# pmac_tx_secure register map
Vendor: Texas Instruments
Peripheral module from a debugger description file (folder CC35X1E).
Registers are 32-bit, access per field, reset 0x0 unless marked. A register's access mark holds for its fields unless they carry their own. Offsets are as the file gives them; lines under a group give offsets from that group; [hi:lo] are bit positions; {n}, {i} and the like mark numbered series; 'fields as' and 'values as' point back to an identical list; <NAME> marks a mode.

## pmac_tx_secure (part 1 of 3)
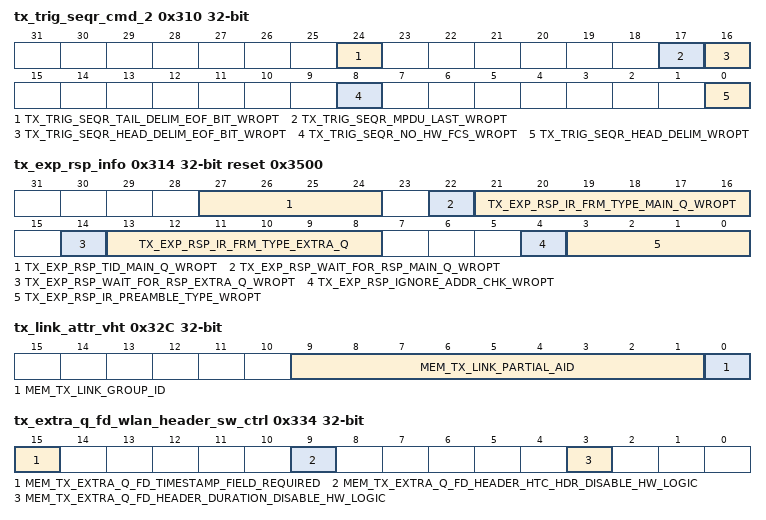
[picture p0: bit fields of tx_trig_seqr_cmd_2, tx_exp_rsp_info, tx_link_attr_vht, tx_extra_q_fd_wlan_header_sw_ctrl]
0x310 tx_trig_seqr_cmd_2
  [24] TX_TRIG_SEQR_TAIL_DELIM_EOF_BIT_WROPT rw — Set 1 - EOF field is present in tail delimiter. Set 0 - EOF field is not present in tail delimiter. EOF (end of frame indication) - When set to 1 in the tail delimiter (or what is called EOF MPDU delimiter) it indicates to the recipient MAC that all MPDUs have been received and that receive processing can cease. Note, tail delimiter present between MPDU in an A-MPDU (due to density requirement) shall set EOF bit to 0, unless it is the last MPDU, and symbol padding is required.
  [17] TX_TRIG_SEQR_MPDU_LAST_WROPT rw — Set 1 - Indicate last transmitted MPDU in current PPDU. Set 0 - Part of A-MPDU, followed by more MPDU in current PPDU,
  [16] TX_TRIG_SEQR_HEAD_DELIM_EOF_BIT_WROPT rw — Set 1 - EOF field is present in head delimiter. Set 0 - EOF field is not present in head delimiter. EOF (end of frame indication) - this field is present in MPDU head delimiter and have several usages: 1. VHT/HE : S-MPDU in VHT/HE PPDU is always carried in an A-MPDU structure , the EOF in the head delimiter is used to indicate that this A-MPDU is a Single MPDU (S-MPDU). Meaning EOF bit in head delimiter will be always set to 1, regardless of whether it requires an ACK or NOT. 2. HE : A-MPDU in VHT/HE PPDU, the EOF bit is used to determine whether certain MPDUs in the transmitted aggregation solicit an ACK response. 3. HT : A-MPDU in HT PPDU, EOF in Head delimiter is always set to 0.
  [8] TX_TRIG_SEQR_NO_HW_FCS_WROPT rw — Set 1 - FCS will be inserted at the end of frame. Set 0 - Otherwise.
  [0] TX_TRIG_SEQR_HEAD_DELIM_WROPT rw — Set 1 - TX Sequencer will insert Head Delimiter to current transmitted MPDU. Set 0 - TX Sequencer will not insert Head Delimiter to current transmitted MPDU. 0 - 11n/legacy MPDU. 1 - 11n/11ax/11ac A-MPDU or when sending S-MPDU (11ax/11ac).
0x314 tx_exp_rsp_info reset 0x3500
  [27:24] TX_EXP_RSP_TID_MAIN_Q_WROPT rw — This value is set by the TX Trigger module, and determine the TID of the QoS Data frames that were transmitted from main queue.
  [22] TX_EXP_RSP_WAIT_FOR_RSP_MAIN_Q_WROPT rw — This value is set by the TX Trigger module, and determine if there is a need to wait for a response for the transmitted frame from the main queue.
  [21:16] TX_EXP_RSP_IR_FRM_TYPE_MAIN_Q_WROPT rw — Expected response frame type, this value is set by the TX Trigger module, and used by the TX status machine/Exchange to determine the tx status of the transmitted frame. This value is set when transmitting a frame from the main queue in a complex aggregation constellation.
  [14] TX_EXP_RSP_WAIT_FOR_RSP_EXTRA_Q_WROPT rw — This value is set by the TX Trigger module, and determine if there is a need to wait for a response for the transmitted frame from the extra queue.
  [13:8] TX_EXP_RSP_IR_FRM_TYPE_EXTRA_Q ro — Expected response frame type, this value is set by the TX Trigger module, and used by the TX status machine/Exchange to determine the tx status of the transmitted frame. This value is set when transmitting a frame (mngt/ctrl frames) from the extra queue in a complex aggregation constellation.
  [4] TX_EXP_RSP_IGNORE_ADDR_CHK_WROPT rw — This value is set by the TX Trigger module and determines if there is a need to compare received address. This bit is needed as some responses can be transmitted by peer as a broadcast.
  [3:0] TX_EXP_RSP_IR_PREAMBLE_TYPE_WROPT rw — Expected response preamble, this value is set by the TX Trigger module, and used by the access module to load RX timeout counter with the appropriate value. Note, the time for the response to arrive (indication to PMAC) depends on the length and rate of the response preamble.
0x318 tx_exp_rsp_ra_h ro
  [15:0] TX_EXP_RSP_RA_H — Expected response receive address (47:32) set by TX Trigger module for the use of TX status machine. This value is compared in the TX status machine with the actual recieved address, to determine tx status.
0x31C tx_exp_rsp_ra_l ro
  [31:0] TX_EXP_RSP_RA_L — Expected response receive address (31:0) set by TX Trigger module for the use of TX status machine. This value is compared in the TX status machine with the actual recieved address, to determine tx status.
0x320 tx_trig_pre_fec_mac_pad
  [15:0] TX_TRIG_PRE_FEC_MAC_PAD_WROPT rw — Number of padding bytes done by the PMAC , the pad bytes are required when the transmitted tx frame length is missing bytes to complete certain constellation symbols. This value is retrieved from Duration Calculation module by the TX Trigger module. This value is passed to the TX Sequencer, which performs the padding (up to 3 octets or using tail-delimiters).
0x324 tx_role_mac_addr_msb
  [15:0] MEM_TX_ROLE_MAC_ADDR_MSB rw — MAC address (47:32) set by SW in Role DB, used by trigger module as TA field in WLAN header when generating QoS-Null frames.
0x328 tx_role_mac_addr_lsb rw
  [31:0] MEM_TX_ROLE_MAC_ADDR_LSB — MAC address (32:0) set by SW in Role DB, used by trigger module as TA field in WLAN header when generating QoS-Null frames.
0x32C tx_link_attr_vht
  [9:1] MEM_TX_LINK_PARTIAL_AID rw — Partial AID is included in SU to provide an earlier indication to the PHY so it can determine if it is the intended recipient of the packet. The MAC configures the PHY with the value that identifies the STA. Addressed to AP: BSSID[39:47] Addressed to Mesh STA: RA[39:47] Addressed to STA: (AID + (BSSID[44:47] xor BSSID[40:43]) << 5) mod 2^9
  [0] MEM_TX_LINK_GROUP_ID rw — Set Group-ID bit: 0 - vht_sig_a1[9:4] = 6'b000000 (dec 0 ) 1 - vht_sig_a1[9:4] = 6'b111111 (dec 63 )
0x330 tx_scrpt_hw_indication_sel
  [0] TX_SCRPT_HW_INDICATION_SEL_WROPT rw — Select HW indication group. Initial value on each script start is attribute bit 2 value. Set 0 - First Group. Set 1 - Second Group.
0x334 tx_extra_q_fd_wlan_header_sw_ctrl
  [15] MEM_TX_EXTRA_Q_FD_TIMESTAMP_FIELD_REQUIRED rw, [9] MEM_TX_EXTRA_Q_FD_HEADER_HTC_HDR_DISABLE_HW_LOGIC rw, [3] MEM_TX_EXTRA_Q_FD_HEADER_DURATION_DISABLE_HW_LOGIC rw
0x338 tx_ac4_queue_acc_length rw
  [31:0] TX_AC4_QUEUE_ACC_LENGTH_WROPT
0x33C tx_ac5_queue_acc_length rw
  [31:0] TX_AC5_QUEUE_ACC_LENGTH_WROPT
0x340 tx_ac_queue_inc_dec_length
  [17:0] TX_AC_QUEUE_INC_DEC_LENGTH_WROPT rw — Increment or decrement specific AC queue length. [13:0]: Number of bytes to increment/decrement [16:14]: Select AC [17]: Select operation. 0x0 Decrement. 0x1 Increment
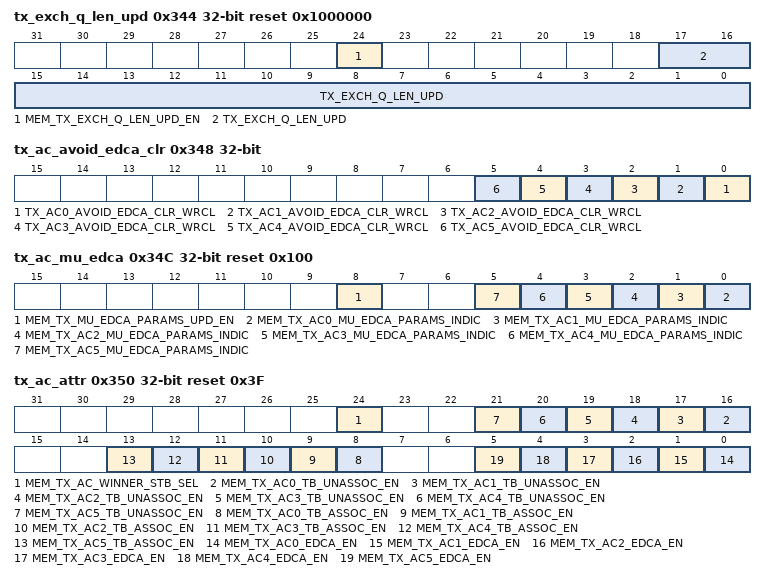
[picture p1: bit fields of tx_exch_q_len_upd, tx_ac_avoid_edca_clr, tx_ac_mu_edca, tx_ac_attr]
0x344 tx_exch_q_len_upd reset 0x1000000
  [24] MEM_TX_EXCH_Q_LEN_UPD_EN rw — Enable Tx exchange HW to decrement AC queue length when necessary
  [17:0] TX_EXCH_Q_LEN_UPD ro — TX exchange queue length update [13:0]: Number of bytes to increment/decrement [16:14]: Select AC [17]: Select operation. 0x0 Decrement. 0x1 Increment
0x348 tx_ac_avoid_edca_clr — writing '1' to one of the bits will create a pulse that will clear EDCA avoidance bit in AC_CTRL Machine.
  [n] TX_AC{n}_AVOID_EDCA_CLR_WRCL wo (n=0..5)
0x34C tx_ac_mu_edca reset 0x100
  [8] MEM_TX_MU_EDCA_PARAMS_UPD_EN rw — Set 0 : MU EDCA parameters replacement is not enabled. Set 1 : MU EDCA parameters replacement is enabled. HW will trigger IRQ to SW if one of the AC was seleted for the last TB transmition, and parameter update is required. AC CTRL FSM will avoid competing for 'AIR' untill SW clears the AVOID EDCA bit. Note, although AC is not competing for transmission, candidate/exchange are still operating on this AC in order to clear expired frames.
  [n] MEM_TX_AC{n}_MU_EDCA_PARAMS_INDIC rw (n=0..5) — Set 0 : Regular EDCA 'air competition' parameters are set by SW. Set 1 : Worst EDCA 'air competition' parameters are set by SW.
0x350 tx_ac_attr reset 0x3F
  [24] MEM_TX_AC_WINNER_STB_SEL rw — Set 0 : All AC Manager CTRL use tx_winner_stb. (Default - As Legacy LSB-PG1) Set 1 : All AC Manager CTRL use tx_winner_stb_synched. (New Option for LSB-PG2)
  [n+16] MEM_TX_AC{n}_TB_UNASSOC_EN rw (n=0..5) — Set 1 : AC is allowed to participate in TB un-associated transmission. Set 0 : O.W.
  [n+8] MEM_TX_AC{n}_TB_ASSOC_EN rw (n=0..5) — Set 1 : AC is allowed to participate in TB associated transmission. Set 0 : O.W.
  [n] MEM_TX_AC{n}_EDCA_EN rw (n=0..5) — Set 1 : AC is allowed to compete for EDCA transmission. Set 0 : O.W.
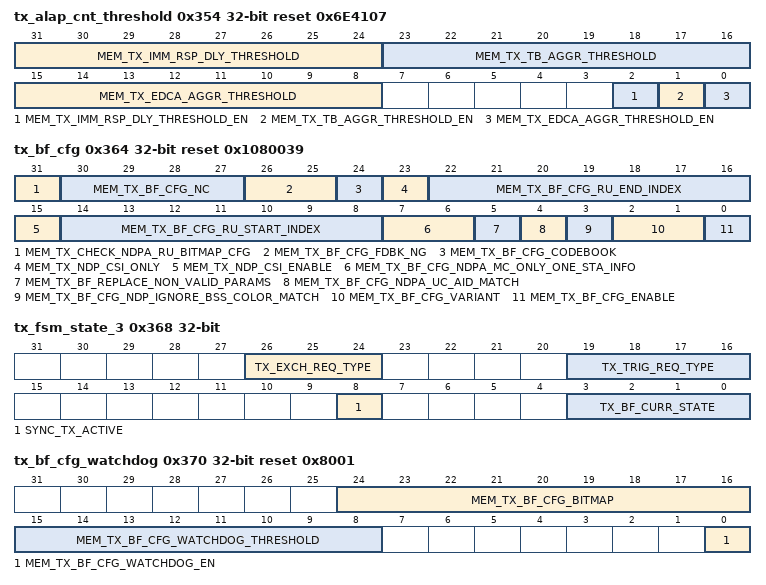
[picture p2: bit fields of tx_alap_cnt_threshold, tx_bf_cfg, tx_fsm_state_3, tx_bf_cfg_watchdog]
0x354 tx_alap_cnt_threshold reset 0x6E4107 — The ALAP Counter purpose is to sync HW to a certain point of time after tx winner. counter resolution is 1/5 us. count clear - on every tx winner. count increment - increment every useddiv_stb up to 256 (51 us). upon reaching a thresholds, done indication is generated. tx_alap_ctr_imm_rsp_dly_dn - scripter HW indication. tx_alap_ctr_tb_aggr_dn - aggregation machine in TX trigger will stop adding frames to TB aggregation. tx_alap_ctr_edca_aggr_dn - aggregation machine in TX trigger will stop adding frames to EDCA aggregation.
  [31:24] MEM_TX_IMM_RSP_DLY_THRESHOLD rw
  [23:16] MEM_TX_TB_AGGR_THRESHOLD rw — TB data ready is 29.8 us
  [15:8] MEM_TX_EDCA_AGGR_THRESHOLD rw — EDCA length ready is after 15.6us.
  [2] MEM_TX_IMM_RSP_DLY_THRESHOLD_EN rw
  [1] MEM_TX_TB_AGGR_THRESHOLD_EN rw
  [0] MEM_TX_EDCA_AGGR_THRESHOLD_EN rw
0x358 tx_hw_gen_frm_8 ro
0x35C tx_hw_gen_frm_9 ro
0x360 tx_bf_rpt_pload_ptr reset not defined — location of HW generated BF report by PHY modules.
  [23:2] MEM_TX_BF_RPT_PLOAD_PTR rw — 0x4592_DC00 (full address).
0x364 tx_bf_cfg rw reset 0x1080039
  [31] MEM_TX_CHECK_NDPA_RU_BITMAP_CFG — If set check validity of ndpa ru_bitmap for eht.
  [30:27] MEM_TX_BF_CFG_NC — Indicates the number of columns Nc, in the BF feedback matrix minus 1. Set to 0 - Osprey has single antenna.
  [26:25] MEM_TX_BF_CFG_FDBK_NG — Feedback type and Ng: Set 0 - SU report with 4 sub-carrier grouping. Set 1 - SU report with 16 sub-carrier grouping. Set 2 - MU, Not supported. Set 3 - CQI report. (with Codebook set to 0).
  [24] MEM_TX_BF_CFG_CODEBOOK — Feedback quantization: Set 0 - (4,2) Set 1 - (6,2)
  [23] MEM_TX_NDP_CSI_ONLY — Set to 1 - To force all ndp to generate CSI (no beamforming) Set to 0 - Disable this option. CSI can still be generating by non BF ndp if MEM_TX_NDP_CSI_ENABLE set
  [22:16] MEM_TX_BF_CFG_RU_END_INDEX — The last index indicates the last 26-tone RU for which the BFee is generating feedback report. 0-8 - 26-tone RU 1-9 9-127 reserved
  [15] MEM_TX_NDP_CSI_ENABLE — Set to 1 - to enable generating CSI from all NDP not valid for BF Set to 0 - to disable generating CSI from all NDP not valid for BF
  [14:8] MEM_TX_BF_CFG_RU_START_INDEX — The start index indicates the first 26-tone RU for which the BFee is generating feedback report. 0-8 - 26-tone RU 1-9 9-127 reserved
  [7:6] MEM_TX_BF_CFG_NDPA_MC_ONLY_ONE_STA_INFO — In case we receive NDPA with brodcast RA (with aid match) and only one STA info element, this 2 configuration bit decide on the performed flow (TB or immediate report) and on weather to use and not use STA info element. Bit 0 (Bit 6) - Flow Selection: Set 0 - TB sounding flow. Set 1 - Non-TB (immediate) souding flow. Bit 1 (Bit 7) - Parameter Selection: Set to 0 - use parameters from STA info element. Set to 1 - use parameters from configuration registers.
  [5] MEM_TX_BF_REPLACE_NON_VALID_PARAMS — If set to 1 - in case BF parameters from NDPA are not valid, BF module will start a BF flow and replace them with configurated parameters. If set to 0 - in case BF parameters from NDPA are not valid, BF module will not start a BF flow.
  [4] MEM_TX_BF_CFG_NDPA_UC_AID_MATCH — In case we receive NDPA with unicast RA and aid match on one of the STA info elements, this bit deciede which BF parameters to use. Set to 0 - use parameters from STA info element. Set to 1 - use parameters from configuration registers.
  [3] MEM_TX_BF_CFG_NDP_IGNORE_BSS_COLOR_MATCH — If set to 1 - BF HW will ignore check on BSS color match of the recieved NDP. If set to 0 - NDP frame must have a matching BSS color for successfull sounding frame exchange.
  [2:1] MEM_TX_BF_CFG_VARIANT — Set to 11 for EHT, otherwise - HE
  [0] MEM_TX_BF_CFG_ENABLE — Set to 1 - to enable response to a beamforming sounding protocol. Set to 0 - to disable response to a beamforming sounding protocol.
0x368 tx_fsm_state_3 ro
  [26:24] TX_EXCH_REQ_TYPE — 3'h0 : TX_EXCH_REQ_NO_PROT 3'h1 : TX_EXCH_REQ_TB_DATA 3'h2 : TX_EXCH_REQ_CTS 3'h3 : TX_EXCH_REQ_RTS 3'h4 : TX_EXCH_REQ_CF_END 3'h5 : TX_EXCH_REQ_IMM_RSP 3'h6 : TX_EXCH_REQ_QOS_NULL
  [19:16] TX_TRIG_REQ_TYPE — 4'h0 : EDCA_PROT // First data frame, requires protection 4'h1 : EDCA_DATA // First data frame, not requiring protection 4'h2 : NEXT_AGGR_DATA 4'h3 : CF_END 4'h4 : IMM_RESP 4'h5 : BURST // Ongoing burst 4'h6 : BURST_POST_PROT // First frame in a potential burst 4'h7 : BURST_POST_PROT_SIGNLE// Not a 'real' burst, only a CTS-DATA or RTS-CTS-DATA 4'h8 : TB_DATA // Trigger Based Data Transmission 4'h9 : TB_REPORT // Trigger Based Report (QoS-Null Response) 4'hA : TB_RESP // Trigger Based Response (ACK/BA/etc Response) 4'hB : TB_NDP_REPORT // Trigger Based Report (Null Data Packet Response)
  [8] SYNC_TX_ACTIVE — sampled tx_active
  [3:0] TX_BF_CURR_STATE — 4'h0 : TX_BF_IDLE 4'h1 : TX_CSI_NDPA_DETECTED 4'h2 : TX_CSI_NDP_DETECTED 4'h3 : TX_BF_NDPA_DETECTED 4'h4 : TX_BF_NDP_DETECTED 4'h5 : TX_BF_PHY_PARAMS_RDY 4'h6 : TX_BF_PHY_CALC_DONE 4'h7 : TX_BF_WAIT_BFRP 4'h8 : TX_BF_WAIT_TX_DONE
0x36C tx_scrpt_dbg_bus ro — BUS1: 24'b0 curr_buf1_ld_state curr_buf2_ld_state curr_buf3_ld_state curr_buf4_ld_state BUS2: Bit 0 - curr_cmd_is_jmp Bit 1 - jne Bit 2 - je Bit 3 - jge Bit 4 - lnk Bit 5 - jmp_cmd Bit 6 - jmp_completed Bit 7 - pending_jmp Bit 8 - jmp_indic_vld Bit 9 - scrpt_code_ocpm_mcmd_r Bit 10 - lnk_completed Bit 19:11 - scrpt_cnt[8:0] Bit 22:20 - src_sel[2:0] Bit 23 - jmp_indic_vld
0x370 tx_bf_cfg_watchdog reset 0x8001
  [24:16] MEM_TX_BF_CFG_BITMAP rw — BF CFG BITMAP for HE (Active when mem_tx_bf_cfg_variant != '11'): - Bit[0] - bf_sub_ch_bitmap_exist - Bits[8:1] - bf_sub_ch_bitmap BF CFG BITMAP for EHT (Active when mem_tx_bf_cfg_variant == '11'): - Bits[8:0] - bf_partial_bw_info
  [15:8] MEM_TX_BF_CFG_WATCHDOG_THRESHOLD rw — Threshold value in microseconds.
  [0] MEM_TX_BF_CFG_WATCHDOG_EN rw — Watchdog monitor states waiting for input from PHY. TX_BF_NDPA_DETECTED - In case NDP was not received. TX_BF_NDP_DETECTED - In case PHY params ready was not asserted. TX_BF_PHY_PARAMS_RDY - In case PHY calc done was not asserted. Set to 1 - Enable BF FSM watchdog timer. Set to 0 - Disable BF FSM watchdog timer.
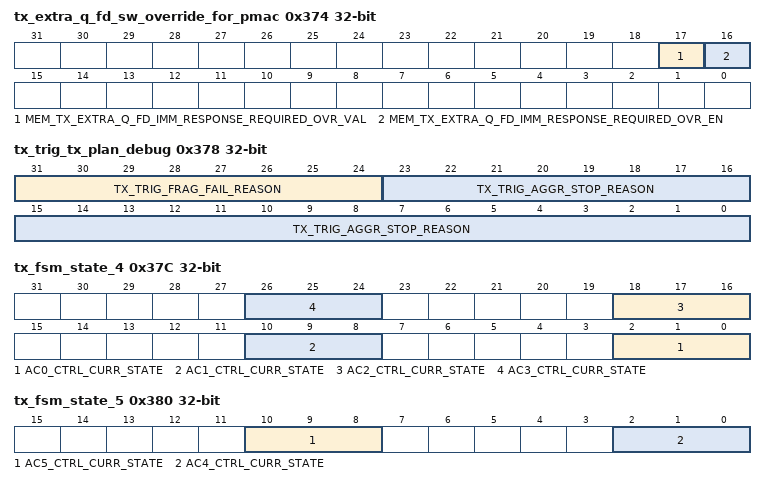
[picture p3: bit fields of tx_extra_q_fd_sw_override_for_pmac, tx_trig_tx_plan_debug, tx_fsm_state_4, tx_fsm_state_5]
0x374 tx_extra_q_fd_sw_override_for_pmac
  [17] MEM_TX_EXTRA_Q_FD_IMM_RESPONSE_REQUIRED_OVR_VAL rw — If override enable bit is set - this bit will set the value - 0 - no imm response is required. 1 - imm response is required.
  [16] MEM_TX_EXTRA_Q_FD_IMM_RESPONSE_REQUIRED_OVR_EN rw — SW override PMAC decision either imm response is required for this frame. (Type & rate of the expected response will be calculated by HW. Only the necessity can be overridden through descriptor).
0x378 tx_trig_tx_plan_debug ro — In EDCA/TB Transmission, TX Trigger calculate the TX Plan (Aggregation calculation decision) before starting to transmit frames to the AIR.
  [31:24] TX_TRIG_FRAG_FAIL_REASON — Bit 5 - Expected remaining pload is >= than minimum threshold. Bit 4 - Fragment length is >= than minimum threshold. Bit 3 - Current fragment number is less than 4'hF, i.e. next assigned fragment number is at most 4'hF. In case retry on frag, no need for new fragment number. Bit 2 - In case QoS-null was added --> check MPDU length, else check frame length (as it is last transmitted in aggregation). Bit 1 - Check frag length is valid for AES/DMA (won't create underflow with PHY reads). Bit 0 - Means that MAC Header (+FCS/Delimiter) can't fit into remaining A-MPDU bytes.
  [23:0] TX_TRIG_AGGR_STOP_REASON — Bit 13 - Expired Frame Bit 12 - Immediate Expiry Frame Bit 11 - Sequence number is out of BA window. Bit 10 - Frame Type is not QoS-Data. Bit 9 - Frame is forbidden in aggregation. Bit 8 - Wi-Fi Priority is higher than 7. Bit 7 - Frame length can't fit in A-MPDU remaining bytes Bit 6 - MPDU length (Frame Length with Density/Padding) can't fit in A-MPDU remaining bytes Bit 5 - Frame payload length is to small, will create underflow due to races between the AES and PHY read. Bit 4 - Frame is Fragmented, and not valid to be part of aggregation. Bit 3 - Number of MPDUs in aggregation reached maximum. Bit 2 - Next Frame in queue doesn't exists. Bit 1 - Dynamic Limiter Done Bit 0 - Main Queue Frame Requires ACK and Multi-TID is zero.
0x37C tx_fsm_state_4 ro
  [8n+2:8n] AC{n}_CTRL_CURR_STATE (n=0..3) — 0: TX_AC_CTRL_IDLE 1: TX_AC_CTRL_WAIT_CAND_DN 2: TX_AC_CTRL_WAIT_TX_START 4: TX_AC_CTRL_WAIT_TX_DN 5: TX_AC_CTRL_WAIT_EXPIRY_DN
0x380 tx_fsm_state_5 ro
  [10:8] AC5_CTRL_CURR_STATE — 0: TX_AC_CTRL_IDLE 1: TX_AC_CTRL_WAIT_CAND_DN 2: TX_AC_CTRL_WAIT_TX_START 4: TX_AC_CTRL_WAIT_TX_DN 5: TX_AC_CTRL_WAIT_EXPIRY_DN
  [2:0] AC4_CTRL_CURR_STATE — 0: TX_AC_CTRL_IDLE 1: TX_AC_CTRL_WAIT_CAND_DN 2: TX_AC_CTRL_WAIT_TX_START 4: TX_AC_CTRL_WAIT_TX_DN 5: TX_AC_CTRL_WAIT_EXPIRY_DN
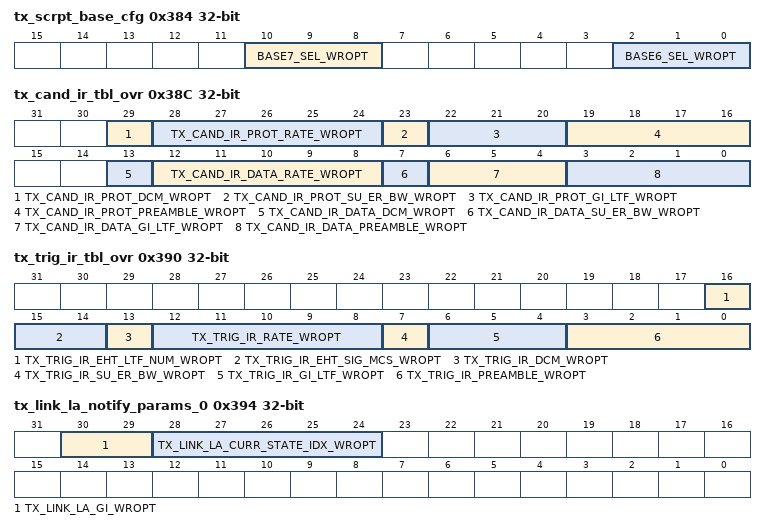
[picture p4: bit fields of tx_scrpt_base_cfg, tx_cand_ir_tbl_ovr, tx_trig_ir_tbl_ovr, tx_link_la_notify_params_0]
0x384 tx_scrpt_base_cfg reset not defined
  [10:8] BASE7_SEL_WROPT rw — 0: base7 points to mem_tx_fd_adress. 1: base7 points to gen_base7. 2: base7 points to the HW generated frames pionter. selector self clears to 0 on scrpt_start_stb
  [2:0] BASE6_SEL_WROPT rw — 2'b00 scripter's base 6 points to {gen_base7[23:2, 2'b0} used by the tx_trigger for fetching unaligned header bytes 2'b01 scripter's base 6 points to Base6[23:0] + 4 X gen_prpose_idx 2'b10 scripter's base 6 points to Base6[23:0] + security header additional offset (sum of: +2 for QC, +6 for A4, +4 for HTC header) self clears to 2'b00 at scrpt_start_stb 2'b11 scripter's base 6 points to address 0xd88000 - MMU cyclic debug buffer
0x388 tx_tb_max_ppdu_length reset not defined — Restirct the maximum allowed PPDU length in TB transmission.
  [15:0] MEM_TX_TB_MAX_PPDU_LENGTH rw — max ppdu length in bytes
0x38C tx_cand_ir_tbl_ovr — Writing this register field will override IR Table reposone to candidate request.
  [29] TX_CAND_IR_PROT_DCM_WROPT rw, [28:24] TX_CAND_IR_PROT_RATE_WROPT rw, [23] TX_CAND_IR_PROT_SU_ER_BW_WROPT rw, [22:20] TX_CAND_IR_PROT_GI_LTF_WROPT rw, [19:16] TX_CAND_IR_PROT_PREAMBLE_WROPT rw, [13] TX_CAND_IR_DATA_DCM_WROPT rw, [12:8] TX_CAND_IR_DATA_RATE_WROPT rw, [7] TX_CAND_IR_DATA_SU_ER_BW_WROPT rw, [6:4] TX_CAND_IR_DATA_GI_LTF_WROPT rw, [3:0] TX_CAND_IR_DATA_PREAMBLE_WROPT rw
0x390 tx_trig_ir_tbl_ovr — Writing this register field will override IR Table reposone to Trigger request.
  [16] TX_TRIG_IR_EHT_LTF_NUM_WROPT rw, [15:14] TX_TRIG_IR_EHT_SIG_MCS_WROPT rw, [13] TX_TRIG_IR_DCM_WROPT rw, [12:8] TX_TRIG_IR_RATE_WROPT rw, [7] TX_TRIG_IR_SU_ER_BW_WROPT rw, [6:4] TX_TRIG_IR_GI_LTF_WROPT rw, [3:0] TX_TRIG_IR_PREAMBLE_WROPT rw
0x394 tx_link_la_notify_params_0
  [30:29] TX_LINK_LA_GI_WROPT rw — Hold Guard Interval value: 0: 0.4 us 1: 0.8 us 2: 1.6 us 3: 3.2 us
  [28:24] TX_LINK_LA_CURR_STATE_IDX_WROPT rw — Holds the current state the link is at.
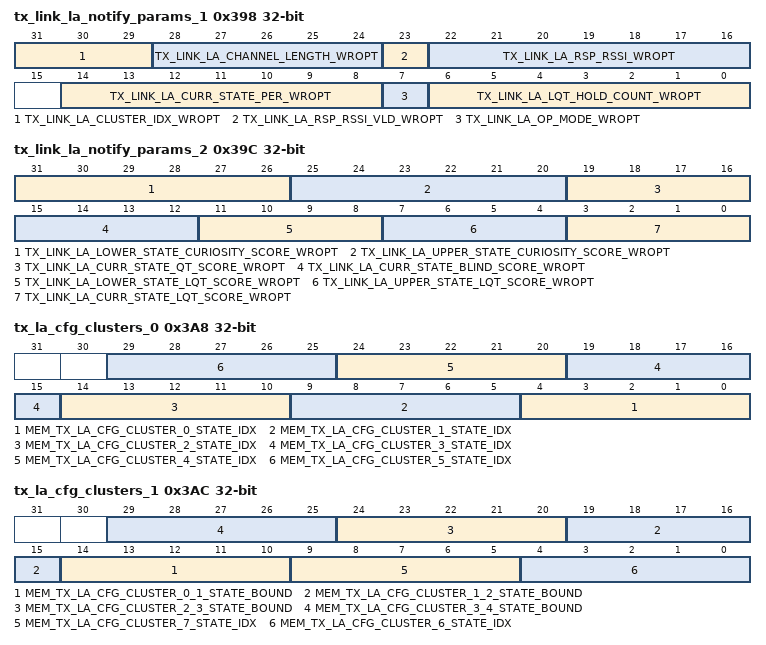
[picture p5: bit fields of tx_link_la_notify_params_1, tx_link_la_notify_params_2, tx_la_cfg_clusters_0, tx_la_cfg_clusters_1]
0x398 tx_link_la_notify_params_1
  [31:29] TX_LINK_LA_CLUSTER_IDX_WROPT rw — Holds cluster index (0-7) value.
  [28:24] TX_LINK_LA_CHANNEL_LENGTH_WROPT rw — Holds channel length value.
  [23] TX_LINK_LA_RSP_RSSI_VLD_WROPT rw — RSSI: 7 bits (0= -110dBm, 127= 17dBm) Response RSSI for ACK, Block ACK and CTS.
  [22:16] TX_LINK_LA_RSP_RSSI_WROPT rw — RSSI: 7 bits (0= -110dBm, 127= 17dBm) Response RSSI for ACK, Block ACK and CTS.
  [14:8] TX_LINK_LA_CURR_STATE_PER_WROPT rw — Holds the current state PER (Packet Error Rate) values. Range 0-1
  [7] TX_LINK_LA_OP_MODE_WROPT rw — Holds the link adaptation mode: 0- means convergence. 1- means functional.
  [6:0] TX_LINK_LA_LQT_HOLD_COUNT_WROPT rw — Holds the LQT counter value in case of LQT limit is reached.
0x39C tx_link_la_notify_params_2 rw
  [31:26] TX_LINK_LA_LOWER_STATE_CURIOSITY_SCORE_WROPT — Holds the current state two Curiosity score values: going up and going down.
  [25:20] TX_LINK_LA_UPPER_STATE_CURIOSITY_SCORE_WROPT — Holds the current state two Curiosity score values: going up and going down.
  [19:16] TX_LINK_LA_CURR_STATE_QT_SCORE_WROPT — Holds QT score for current state. Value is treated as signed.
  [15:12] TX_LINK_LA_CURR_STATE_BLIND_SCORE_WROPT — Holds Blind Convergence score for current state. Value is treated as signed.
  [11:8] TX_LINK_LA_LOWER_STATE_LQT_SCORE_WROPT — Holds the current state three LQT score values: upper state, current state and lower state.
  [7:4] TX_LINK_LA_UPPER_STATE_LQT_SCORE_WROPT — Holds the current state three LQT score values: upper state, current state and lower state.
  [3:0] TX_LINK_LA_CURR_STATE_LQT_SCORE_WROPT — Holds the current state three LQT score values: upper state, current state and lower state.
0x3A0 tx_la_cfg_curr_state_per_weight
  [6:0] MEM_TX_LA_CFG_CURR_STATE_PER_WEIGHT rw
0x3A4 tx_la_cfg_upper_state_per_weight
  [6:0] MEM_TX_LA_CFG_UPPER_STATE_PER_WEIGHT rw
0x3A8 tx_la_cfg_clusters_0
  [5n+4:5n] MEM_TX_LA_CFG_CLUSTER_{n}_STATE_IDX rw (n=0..5) — Holds the LAS (Link Adaptation State) corresponding to the cluster.
0x3AC tx_la_cfg_clusters_1
  [5n+14:5n+10] MEM_TX_LA_CFG_CLUSTER_{n}_{n+1}_STATE_BOUND rw (n=0..3) — Holds the LAS (Link Adaptation State) bound corresponding to transition between two clusters.
  [9:5] MEM_TX_LA_CFG_CLUSTER_7_STATE_IDX rw — Holds the LAS (Link Adaptation State) corresponding to the cluster.
  [4:0] MEM_TX_LA_CFG_CLUSTER_6_STATE_IDX rw — Holds the LAS (Link Adaptation State) corresponding to the cluster.
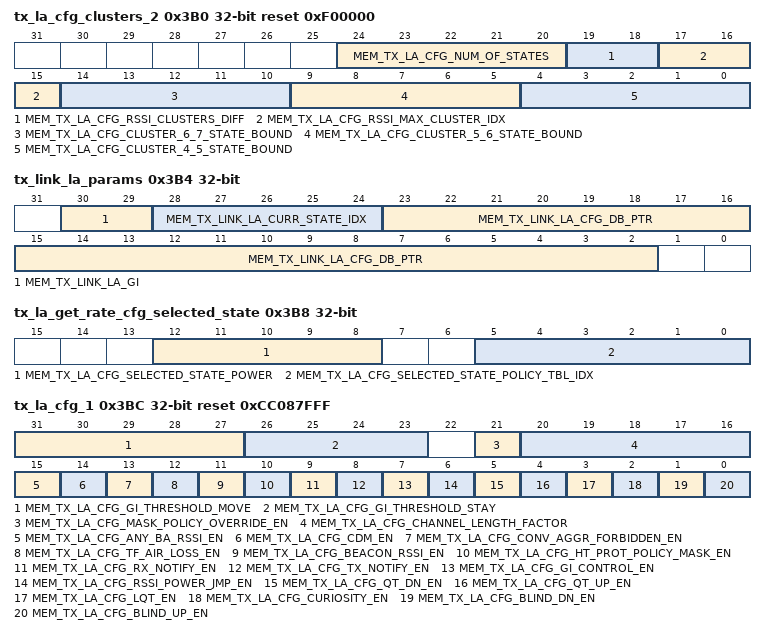
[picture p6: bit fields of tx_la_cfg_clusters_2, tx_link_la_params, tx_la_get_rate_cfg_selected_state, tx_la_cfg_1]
0x3B0 tx_la_cfg_clusters_2 reset 0xF00000
  [24:20] MEM_TX_LA_CFG_NUM_OF_STATES rw — Number of LAS states used
  [19:18] MEM_TX_LA_CFG_RSSI_CLUSTERS_DIFF rw
  [17:15] MEM_TX_LA_CFG_RSSI_MAX_CLUSTER_IDX rw
  [14:10] MEM_TX_LA_CFG_CLUSTER_6_7_STATE_BOUND rw — Holds the LAS (Link Adaptation State) bound corresponding to transition between two clusters.
  [9:5] MEM_TX_LA_CFG_CLUSTER_5_6_STATE_BOUND rw — Holds the LAS (Link Adaptation State) bound corresponding to transition between two clusters.
  [4:0] MEM_TX_LA_CFG_CLUSTER_4_5_STATE_BOUND rw — Holds the LAS (Link Adaptation State) bound corresponding to transition between two clusters.
0x3B4 tx_link_la_params
  [30:29] MEM_TX_LINK_LA_GI rw — Hold Guard Interval value: 0: 0.4 us 1: 0.8 us 2: 1.6 us 3: 3.2 us
  [28:24] MEM_TX_LINK_LA_CURR_STATE_IDX rw — Holds the current state the link is at.
  [23:2] MEM_TX_LINK_LA_CFG_DB_PTR rw — Hold the pointer for LA coniguration DB.
0x3B8 tx_la_get_rate_cfg_selected_state
  [12:8] MEM_TX_LA_CFG_SELECTED_STATE_POWER rw, [5:0] MEM_TX_LA_CFG_SELECTED_STATE_POLICY_TBL_IDX rw
0x3BC tx_la_cfg_1 reset 0xCC087FFF
  [31:27] MEM_TX_LA_CFG_GI_THRESHOLD_MOVE rw — The threshold value for either choosing the RxGI+1 or RxGI+2. The threshold will be in granularity of 50ns and can be negative.
  [26:23] MEM_TX_LA_CFG_GI_THRESHOLD_STAY rw — The threshold value for either choosing the RxGI or RxGI+1. The threshold will be in granularity of 50ns.
  [21] MEM_TX_LA_CFG_MASK_POLICY_OVERRIDE_EN rw — Enabled masking of statistics collection in case of override of short term policies
  [20:16] MEM_TX_LA_CFG_CHANNEL_LENGTH_FACTOR rw — This is the channel length update rule's alpha value in resolution of <1.4>. Max value is 1 (16 integer).
  [15] MEM_TX_LA_CFG_ANY_BA_RSSI_EN rw — set 1 - enable rx notify on Block Acks destinated to other STAs. set 0 - otherwise.
  [14] MEM_TX_LA_CFG_CDM_EN rw — set 1 - enables skipping TX notfiy when collision indication is valid. set 0 - otherwise.
  [13] MEM_TX_LA_CFG_CONV_AGGR_FORBIDDEN_EN rw — set 1 - forbid aggregation transmition during link convergence. set 0 - otherwise.
  [12] MEM_TX_LA_CFG_TF_AIR_LOSS_EN rw — set 1 - enables air loss power jump feature using trigger frames. set 0 - otherwise.
  [11] MEM_TX_LA_CFG_BEACON_RSSI_EN rw — set 1 - enables rssi power jump feature using beacon frames. set 0 - otherwise.
  [10] MEM_TX_LA_CFG_HT_PROT_POLICY_MASK_EN rw — set 1 - enable ht protection policy masking, i.e if HT-Protection is used, we can transmit 11g frames instead of 11n/11ax frames depending on the frame length. set 0 - otherwise
  [9] MEM_TX_LA_CFG_RX_NOTIFY_EN rw — set 1 - enables RX notify by HW. set 0 - otherwise.
  [8] MEM_TX_LA_CFG_TX_NOTIFY_EN rw — set 1 - enable TX notify by HW. set 0 - otherwise.
  [7] MEM_TX_LA_CFG_GI_CONTROL_EN rw — set 1 - enables the GI control update feature. set 0 - otherwise.
  [6] MEM_TX_LA_CFG_RSSI_POWER_JMP_EN rw — set 1 - enables the Power Jump feature. set 0 - otherwise.
  [5] MEM_TX_LA_CFG_QT_DN_EN rw — set 1 - enables the Quick Try Down feature. set 0 - otherwise.
  [4] MEM_TX_LA_CFG_QT_UP_EN rw — set 1 - enables the Quick Try Up Feature. set 0 - otherwise.
  [3] MEM_TX_LA_CFG_LQT_EN rw — set 1 - enables the Limited Quick Try feature. set 0 - otherwise.
  [2] MEM_TX_LA_CFG_CURIOSITY_EN rw — set 1 - enables the Curiosity feature. set 0 - otherwise.
  [1] MEM_TX_LA_CFG_BLIND_DN_EN rw — set 1 - enables the Blind Down feature. set 0 - otherwise.
  [0] MEM_TX_LA_CFG_BLIND_UP_EN rw — set 1 - enables the Blind Up feature. set 0 - otherwise.
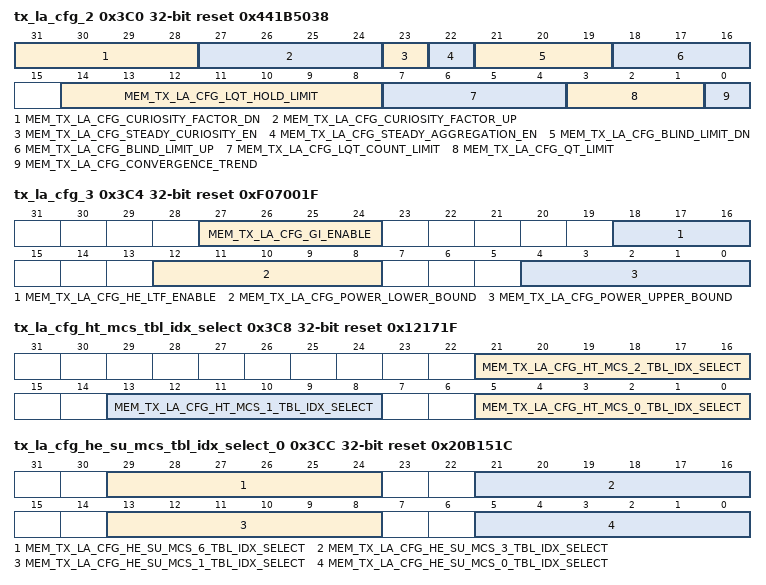
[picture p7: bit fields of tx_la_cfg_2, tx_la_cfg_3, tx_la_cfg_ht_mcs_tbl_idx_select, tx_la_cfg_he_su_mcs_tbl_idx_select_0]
0x3C0 tx_la_cfg_2 reset 0x441B5038
  [31:28] MEM_TX_LA_CFG_CURIOSITY_FACTOR_DN rw — The factor we use to multiply our curiosity down score. Value is <2.2u>.
  [27:24] MEM_TX_LA_CFG_CURIOSITY_FACTOR_UP rw — The factor we use to multiply our curiosity up score. Values are <2.2u>.
  [23] MEM_TX_LA_CFG_STEADY_CURIOSITY_EN rw — set 0 : Steady curiosity mode down - curiosity treats aggragation as usual set 1 : Steady curiosity mode up - curiosity treats aggragation one unit
  [22] MEM_TX_LA_CFG_STEADY_AGGREGATION_EN rw — set 0 : Steady aggragation mode down - quick try and blind convergence mode treat aggragation as usual set 1 : Steady aggragation mode up - quick try and blind convergence mode treat aggragation one unit
  [21:19] MEM_TX_LA_CFG_BLIND_LIMIT_DN rw — Number of successive QT Dn triggering Blind Down mechanism.
  [18:16] MEM_TX_LA_CFG_BLIND_LIMIT_UP rw — Number of successive QT Up triggering Blind Up mechanism.
  [14:8] MEM_TX_LA_CFG_LQT_HOLD_LIMIT rw — Number of transmissions we hold until we release the option to change to a better state again.
  [7:4] MEM_TX_LA_CFG_LQT_COUNT_LIMIT rw — Number of reverse LAS changes (going back to previous LAS) to trigger this feature.
  [3:1] MEM_TX_LA_CFG_QT_LIMIT rw — Number of successive transmissions triggering QT mechanism. The limit is for both QT up and QT down.
  [0] MEM_TX_LA_CFG_CONVERGENCE_TREND rw — set 0 : Convergence Down (in rate) - From Cluster 0 to 7 (High Rate to Low Rate, Wait for First Success). set 1 : Convergence Up (in rate) - From Cluster 6 to 0 (Low Rate to High Rate, Wait for First Failure).
0x3C4 tx_la_cfg_3 reset 0xF07001F
  [27:24] MEM_TX_LA_CFG_GI_ENABLE rw — Enables the GI options. Values are: 0001 - 0.4us 0010 - 0.8us 0100 - 1.6us 1000 - 3.2us
  [18:16] MEM_TX_LA_CFG_HE_LTF_ENABLE rw — Enables the HE-LTF options. HE-LTF types are as the mandatory values at the spec. If GI matching HE-LTF value isn't enabled - we override the HE-LTF enable. Values are: 001 - x1. 010 - x2. 100 - x4.
  [12:8] MEM_TX_LA_CFG_POWER_LOWER_BOUND rw — This is the lowest power output to be set by the LA. Values are shifted to be in range of -10dBm to 20dBm, when 0 equals to -10dBm.
  [4:0] MEM_TX_LA_CFG_POWER_UPPER_BOUND rw — This is the highest power output to be set by the LA. Values are shifted to be in range of -10dBm to 20dBm, when 0 equals to -10dBm.
0x3C8 tx_la_cfg_ht_mcs_tbl_idx_select reset 0x12171F
  [21:16] MEM_TX_LA_CFG_HT_MCS_2_TBL_IDX_SELECT rw — Index of HT MCS2 in the policy table.
  [13:8] MEM_TX_LA_CFG_HT_MCS_1_TBL_IDX_SELECT rw — Index of HT MCS1 in the policy table.
  [5:0] MEM_TX_LA_CFG_HT_MCS_0_TBL_IDX_SELECT rw — Index of HT MCS0 in the policy table.
0x3CC tx_la_cfg_he_su_mcs_tbl_idx_select_0 reset 0x20B151C
  [29:24] MEM_TX_LA_CFG_HE_SU_MCS_6_TBL_IDX_SELECT rw — Index of HE SU MCS6 in the policy table.
  [21:16] MEM_TX_LA_CFG_HE_SU_MCS_3_TBL_IDX_SELECT rw — Index of HE SU MCS3 in the policy table.
  [13:8] MEM_TX_LA_CFG_HE_SU_MCS_1_TBL_IDX_SELECT rw — Index of HE SU MCS1 in the policy table.
  [5:0] MEM_TX_LA_CFG_HE_SU_MCS_0_TBL_IDX_SELECT rw — Index of HE SU MCS0 in the policy table.
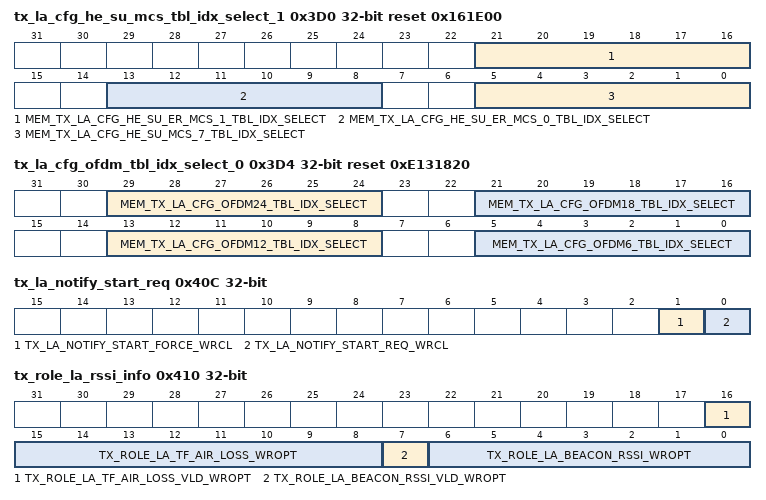
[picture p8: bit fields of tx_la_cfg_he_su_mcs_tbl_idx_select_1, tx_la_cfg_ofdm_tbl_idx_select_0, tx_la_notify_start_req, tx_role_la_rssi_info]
0x3D0 tx_la_cfg_he_su_mcs_tbl_idx_select_1 reset 0x161E00
  [21:16] MEM_TX_LA_CFG_HE_SU_ER_MCS_1_TBL_IDX_SELECT rw — Index of HE SU ER MCS1 in the policy table.
  [13:8] MEM_TX_LA_CFG_HE_SU_ER_MCS_0_TBL_IDX_SELECT rw — Index of HE ER SU MCS0 in the policy table.
  [5:0] MEM_TX_LA_CFG_HE_SU_MCS_7_TBL_IDX_SELECT rw — Index of HE SU MCS7 in the policy table.
0x3D4 tx_la_cfg_ofdm_tbl_idx_select_0 reset 0xE131820
  [29:24] MEM_TX_LA_CFG_OFDM24_TBL_IDX_SELECT rw — Index of OFDM24 in the policy table.
  [21:16] MEM_TX_LA_CFG_OFDM18_TBL_IDX_SELECT rw — Index of OFDM18 in the policy table.
  [13:8] MEM_TX_LA_CFG_OFDM12_TBL_IDX_SELECT rw — Index of OFDM12 in the policy table.
  [5:0] MEM_TX_LA_CFG_OFDM6_TBL_IDX_SELECT rw — Index of OFDM6 in the policy table.
0x3D8 tx_la_cfg_ofdm_tbl_idx_select_1 reset 0x4
  [5:0] MEM_TX_LA_CFG_OFDM54_TBL_IDX_SELECT rw — Index of OFDM54 in the policy table.
{0x3D4+8i} tx_la_cfg_short_term_policy_mask_lsb_{i} rw (i=1..6)
  [31:0] MEM_TX_LA_CFG_SHORT_TERM_POLICY_MASK_LSB_{i}
{0x3D8+8i} tx_la_cfg_short_term_policy_mask_msb_{i} (i=1..6)
  [5:0] MEM_TX_LA_CFG_SHORT_TERM_POLICY_MASK_MSB_{i} rw
0x40C tx_la_notify_start_req
  [1] TX_LA_NOTIFY_START_FORCE_WRCL wo — Force TX link adaptation notify request overriding TX la required indication
  [0] TX_LA_NOTIFY_START_REQ_WRCL wo
0x410 tx_role_la_rssi_info
  [16] TX_ROLE_LA_TF_AIR_LOSS_VLD_WROPT rw — Valid signal for RSSI collected from trigger frames for link adaptation (STA only).
  [15:8] TX_ROLE_LA_TF_AIR_LOSS_WROPT rw — RSSI collected from trigger frames for link adaptation (STA only).
  [7] TX_ROLE_LA_BEACON_RSSI_VLD_WROPT rw — Valid signal for RSSI collected from beacon frames for link adaptation (STA only).
  [6:0] TX_ROLE_LA_BEACON_RSSI_WROPT rw — RSSI collected from beacon frames for link adaptation (STA only).
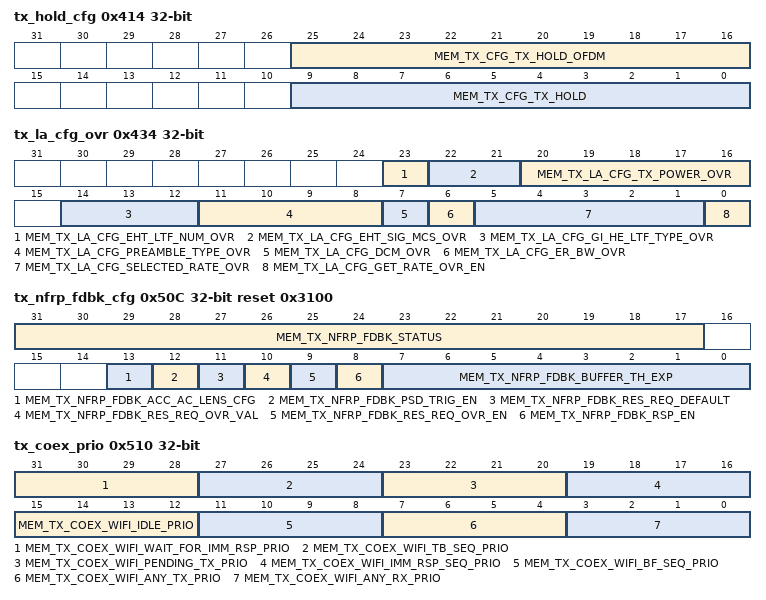
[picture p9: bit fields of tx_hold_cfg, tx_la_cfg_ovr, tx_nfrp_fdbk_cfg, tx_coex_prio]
0x414 tx_hold_cfg reset not defined — Hold Time Register (TX_HOLD_CFG)
  [25:16] MEM_TX_CFG_TX_HOLD_OFDM rw — Hold time for OFDM frame
  [9:0] MEM_TX_CFG_TX_HOLD rw — Hold time for non-OFDM frame
0x418 tx_psd_ctrl
  [0] MEM_TX_PSD_MODE_UPSD_SEL rw — this bit select between UPSD and legacy mode (common to rx and tx). 0: legacy mode 1: UPSD mode
0x41C tx_scr_pad0 rw — Scratch Pad Registers
  [31:0] MEM_TX_SCR_PAD0_WROPT — Scratch Pad Register. These registers provide general_purpose scratch pad register space for eCPU and host access.
0x420 tx_scr_pad0_clr wo — Scratch Pad Clear Register
  [31:0] TX_SCR_PAD0_CLR_WRCL — Scratch Pad0 Clear. Bit-wise CLEAR for Scratch Pad register.
0x424 tx_scr_pad0_set wo — Scratch Pad 4 Set Register
  [31:0] TX_SCR_PAD0_SET_WRCL — Scratch Pad0 Set. Bit-wise SET for Scratch Pad Register.
{0x428+4i} tx_la_debug_bus_{i} ro (i=0..2)
  [27:0] TX_LA_DEBUG_BUS_{i}
0x434 tx_la_cfg_ovr reset not defined
  [23] MEM_TX_LA_CFG_EHT_LTF_NUM_OVR rw
  [22:21] MEM_TX_LA_CFG_EHT_SIG_MCS_OVR rw
  [20:16] MEM_TX_LA_CFG_TX_POWER_OVR rw
  [14:12] MEM_TX_LA_CFG_GI_HE_LTF_TYPE_OVR rw
  [11:8] MEM_TX_LA_CFG_PREAMBLE_TYPE_OVR rw
  [7] MEM_TX_LA_CFG_DCM_OVR rw
  [6] MEM_TX_LA_CFG_ER_BW_OVR rw
  [5:1] MEM_TX_LA_CFG_SELECTED_RATE_OVR rw
  [0] MEM_TX_LA_CFG_GET_RATE_OVR_EN rw — Set 1 - Override the get rate module outputs Set 0 - Otherwise
0x438 tx_la_tx_notify_burst_state_idx
  [4:0] TX_LA_TX_NOTIFY_BURST_STATE_IDX_WROPT rw — Burst next state index in convergence (convergence trend is first failure).
0x504 tx_wlan_hdr_bar_ctrl
  [15:12] MEM_TX_WLAN_HDR_BAR_CTRL_TID rw
0x508 tx_aes_sec_hdr_pn_incr
  [0] TX_AES_SEC_HDR_PN_INCR_WRCL wo — Writing 1 to this bit, increments the PN loaded into AES_SEC_HDR registers, as follows: 1. If frame is not fragmented: +1. 2. If frame is already fragmented, i.e. not first fragment: +1. 3. If frame is fragmented and first fragment: +16. In case (1) or (3) PN will updated back to DB.
0x50C tx_nfrp_fdbk_cfg reset 0x3100
  [31:17] MEM_TX_NFRP_FDBK_STATUS rw — NFRP Feedback Status Information (1-15): Bit 1 - 15 - Reserved.
  [13] MEM_TX_NFRP_FDBK_ACC_AC_LENS_CFG rw — Set 0 - To accumulate all 6 ACs, i.e. AC0-5 Set 1 - To accumulate only 4 ACs, I.e. AC0-3
  [12] MEM_TX_NFRP_FDBK_PSD_TRIG_EN rw — Set 1 - Transmitting response to the NFRP type 0 should be handled as PSD trigger transmission. Set 0 - O.W.
  [11] MEM_TX_NFRP_FDBK_RES_REQ_DEFAULT rw — In case AC queue length accumulators are not valid, NFRP feedback should report this value instead of HW logic.
  [10] MEM_TX_NFRP_FDBK_RES_REQ_OVR_VAL rw
  [9] MEM_TX_NFRP_FDBK_RES_REQ_OVR_EN rw — Override NFRP Feedback statue report value in case feedback type is resouce request.
  [8] MEM_TX_NFRP_FDBK_RSP_EN rw — Set 0 - Disable NFRP response, in case we enter Power Save. Set 1 - Enable NFRP response.
  [7:0] MEM_TX_NFRP_FDBK_BUFFER_TH_EXP rw — The resource request buffer threshold value is equal to 2^(Resource Request Buffer Threshold Exponent) octets. SW should set the resource request buffer threshold to equal 256 octets (i.e. set this value to 8) if no NDP Feedback Report Parameter Set element is sent by the AP.
0x510 tx_coex_prio rw
  [31:28] MEM_TX_COEX_WIFI_WAIT_FOR_IMM_RSP_PRIO, [27:24] MEM_TX_COEX_WIFI_TB_SEQ_PRIO, [23:20] MEM_TX_COEX_WIFI_PENDING_TX_PRIO, [19:16] MEM_TX_COEX_WIFI_IMM_RSP_SEQ_PRIO, [15:12] MEM_TX_COEX_WIFI_IDLE_PRIO, [11:8] MEM_TX_COEX_WIFI_BF_SEQ_PRIO, [7:4] MEM_TX_COEX_WIFI_ANY_TX_PRIO, [3:0] MEM_TX_COEX_WIFI_ANY_RX_PRIO
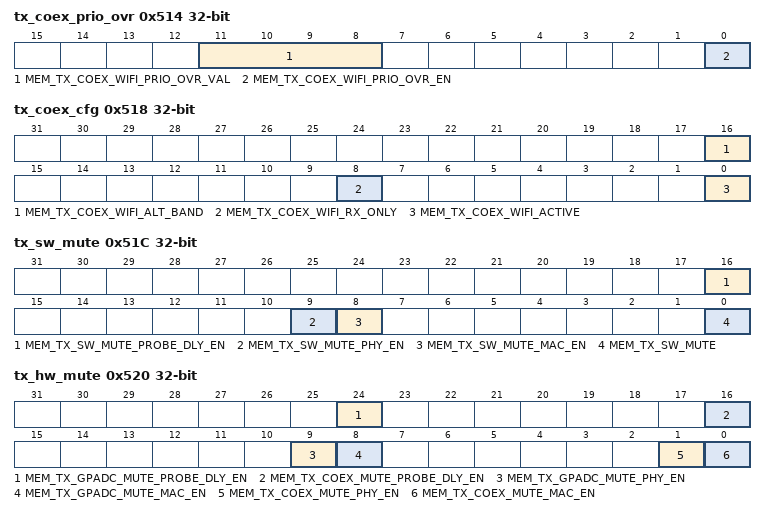
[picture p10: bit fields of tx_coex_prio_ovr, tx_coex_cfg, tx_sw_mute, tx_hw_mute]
0x514 tx_coex_prio_ovr
  [11:8] MEM_TX_COEX_WIFI_PRIO_OVR_VAL rw, [0] MEM_TX_COEX_WIFI_PRIO_OVR_EN rw
0x518 tx_coex_cfg
  [16] MEM_TX_COEX_WIFI_ALT_BAND rw, [8] MEM_TX_COEX_WIFI_RX_ONLY rw, [0] MEM_TX_COEX_WIFI_ACTIVE rw
0x51C tx_sw_mute
  [16] MEM_TX_SW_MUTE_PROBE_DLY_EN rw, [9] MEM_TX_SW_MUTE_PHY_EN rw, [8] MEM_TX_SW_MUTE_MAC_EN rw, [0] MEM_TX_SW_MUTE rw
0x520 tx_hw_mute
  [24] MEM_TX_GPADC_MUTE_PROBE_DLY_EN rw, [16] MEM_TX_COEX_MUTE_PROBE_DLY_EN rw, [9] MEM_TX_GPADC_MUTE_PHY_EN rw, [8] MEM_TX_GPADC_MUTE_MAC_EN rw, [1] MEM_TX_COEX_MUTE_PHY_EN rw, [0] MEM_TX_COEX_MUTE_MAC_EN rw
0x524 tx_coex_mute_clr
  [0] TX_COEX_WIFI_MUTE_CLR_WRCL wo
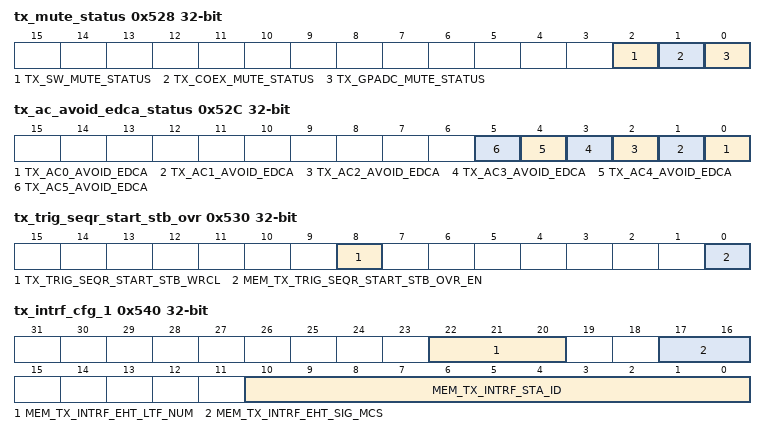
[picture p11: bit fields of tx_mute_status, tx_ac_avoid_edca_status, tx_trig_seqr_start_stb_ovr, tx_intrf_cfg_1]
0x528 tx_mute_status ro
  [2] TX_SW_MUTE_STATUS, [1] TX_COEX_MUTE_STATUS, [0] TX_GPADC_MUTE_STATUS
0x52C tx_ac_avoid_edca_status ro
  [n] TX_AC{n}_AVOID_EDCA (n=0..5)
0x530 tx_trig_seqr_start_stb_ovr
  [8] TX_TRIG_SEQR_START_STB_WRCL wo, [0] MEM_TX_TRIG_SEQR_START_STB_OVR_EN rw
0x540 tx_intrf_cfg_1 reset not defined
  [22:20] MEM_TX_INTRF_EHT_LTF_NUM rw — This register is maped to Tx header word 0 bits 28-30 for EHT-MU EHT-LTF-NUM use purposes.
  [17:16] MEM_TX_INTRF_EHT_SIG_MCS rw — This register is maped to Tx header word 0 bits 21-22 for EHT-MU EHT-SIG-Rate use purposes.
  [10:0] MEM_TX_INTRF_STA_ID rw — This register is maped to Tx header word 1 bits 13-23 for EHT-MU - STA_ID use purposes.
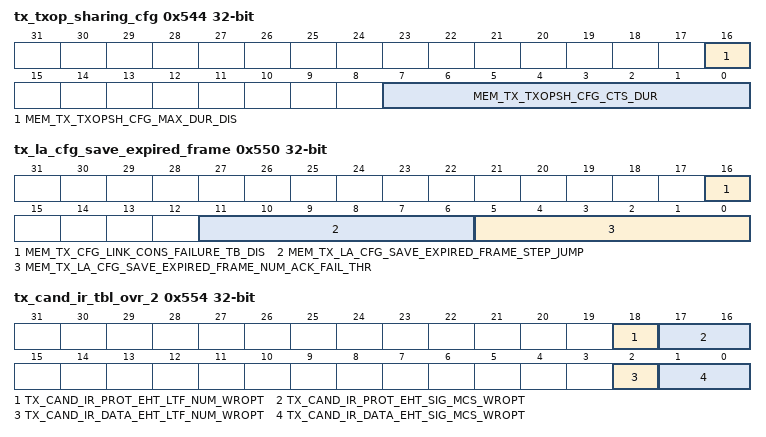
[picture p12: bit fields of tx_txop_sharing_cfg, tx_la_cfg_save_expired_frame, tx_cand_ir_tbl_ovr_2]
0x544 tx_txop_sharing_cfg reset not defined — EHT TXOP-Sharing mode related congifurations
  [16] MEM_TX_TXOPSH_CFG_MAX_DUR_DIS rw — When set to '1' and in TXOP-Sharing mode: trigger aggr calculate MIN for AMPDU_DURATION_LIMIT It disable the "max_ppdu_duration" option. As result - trigger aggr calculate MIN for AMPDU_DURATION_LIMIT will use only MIN (time_to_tsf_end, rx2tx_duration).
  [7:0] MEM_TX_TXOPSH_CFG_CTS_DUR rw — This register is maped to Tx TXOP-Sharing CTS duration Trigger config purposes. (Instead of tx_curr_ac_prot_dur). The default value is 8'd76: 16us (pre SIFS) + 44us (14 bytes packet) + 16us (post SIFS)
0x548 tx_la_cfg_aggreg_mask_lsb rw — Mask Legacy rate for aggregation (lsb)
  [31:0] MEM_TX_LA_CFG_AGGREG_MASK_LSB — Mask Legacy rate for aggragation (lsb bits)
0x54C tx_la_cfg_aggreg_mask_msb — Mask Legacy rate for aggregation (msb)
  [5:0] MEM_TX_LA_CFG_AGGREG_MASK_MSB rw — Mask Legacy rate for aggragation (msb bits)
0x550 tx_la_cfg_save_expired_frame — Save expired frame mechanism configuration
  [16] MEM_TX_CFG_LINK_CONS_FAILURE_TB_DIS rw — Option to disable (exclude) TB packets, from incrementing counter: tx_link_cons_failure_wropt (The counter indicates consecutive failure per link)
  [11:6] MEM_TX_LA_CFG_SAVE_EXPIRED_FRAME_STEP_JUMP rw — The number of la states jumped when save expired frame mechanism is triggered
  [5:0] MEM_TX_LA_CFG_SAVE_EXPIRED_FRAME_NUM_ACK_FAIL_THR rw — Number of ack fails threshold before using save expired frame mechanism
0x554 tx_cand_ir_tbl_ovr_2 — Writing this register field will override IR Table reposone to candidate request.
  [18] TX_CAND_IR_PROT_EHT_LTF_NUM_WROPT rw, [17:16] TX_CAND_IR_PROT_EHT_SIG_MCS_WROPT rw, [2] TX_CAND_IR_DATA_EHT_LTF_NUM_WROPT rw, [1:0] TX_CAND_IR_DATA_EHT_SIG_MCS_WROPT rw
0x600 tx_la_cfg_policy_tbl — Bit 3:0 : preamble Bit 8:4 : rate Bit 9 : dcm Bit 10 : er_bw Bit 12:11 : eht_mcs_sig Bit 13:13 : eht_ltf_num
  [21:0] MEM_TX_LA_CFG_POLICY_TBL_RAM_700_WRMEMP rw
